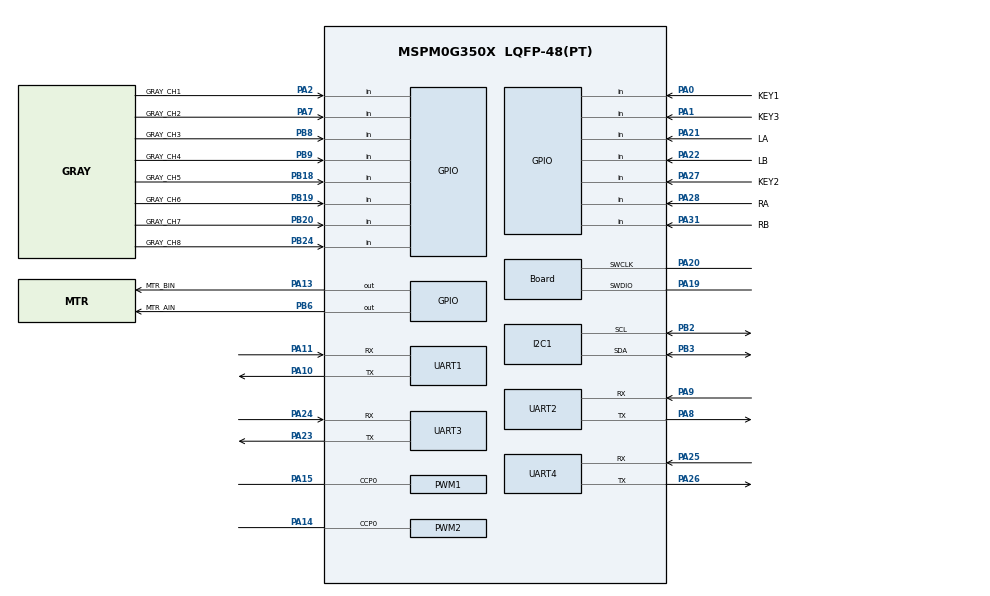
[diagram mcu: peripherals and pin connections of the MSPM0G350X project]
/**
 * @cliArgs --device "MSPM0G350X" --part "Default" --package "LQFP-48(PT)" --product "mspm0_sdk@2.10.00.04"
 * @versions {"tool":"1.26.2+4477"}
 */

/**
 * Import the modules used in this configuration.
 */
const GPIO    = scripting.addModule("/ti/driverlib/GPIO", {}, false);
const GPIO1   = GPIO.addInstance();
const GPIO2   = GPIO.addInstance();
const GPIO3   = GPIO.addInstance();
const GPIO4   = GPIO.addInstance();
const GPIO5   = GPIO.addInstance();
const GPIO6   = GPIO.addInstance();
const I2C     = scripting.addModule("/ti/driverlib/I2C", {}, false);
const I2C1    = I2C.addInstance();
const PWM     = scripting.addModule("/ti/driverlib/PWM", {}, false);
const PWM1    = PWM.addInstance();
const PWM2    = PWM.addInstance();
const SYSCTL  = scripting.addModule("/ti/driverlib/SYSCTL");
const SYSTICK = scripting.addModule("/ti/driverlib/SYSTICK");
const TIMER   = scripting.addModule("/ti/driverlib/TIMER", {}, false);
const TIMER1  = TIMER.addInstance();
const UART    = scripting.addModule("/ti/driverlib/UART", {}, false);
const UART1   = UART.addInstance();
const UART2   = UART.addInstance();
const UART3   = UART.addInstance();
const UART4   = UART.addInstance();

/**
 * Write custom configuration values to the imported modules.
 */
GPIO1.$name                               = "KEY";
GPIO1.port                                = "PORTA";
GPIO1.associatedPins.create(3);
GPIO1.associatedPins[0].$name             = "KEY1";
GPIO1.associatedPins[0].direction         = "INPUT";
GPIO1.associatedPins[0].polarity          = "FALL";
GPIO1.associatedPins[0].interruptPriority = "1";
GPIO1.associatedPins[0].pin.$assign       = "PA0";
GPIO1.associatedPins[1].$name             = "KEY2";
GPIO1.associatedPins[1].direction         = "INPUT";
GPIO1.associatedPins[1].pin.$assign       = "PA27";
GPIO1.associatedPins[2].$name             = "KEY3";
GPIO1.associatedPins[2].direction         = "INPUT";
GPIO1.associatedPins[2].pin.$assign       = "PA1";

const Board                       = scripting.addModule("/ti/driverlib/Board", {}, false);
Board.peripheral.$assign          = "DEBUGSS";
Board.peripheral.swclkPin.$assign = "PA20";
Board.peripheral.swdioPin.$assign = "PA19";

GPIO2.$name                         = "MOTOR_DIR_B";
GPIO2.port                          = "PORTA";
GPIO2.associatedPins[0].$name       = "MTR_BIN";
GPIO2.associatedPins[0].pin.$assign = "PA13";

GPIO3.$name                         = "MOTOR_DIR_A";
GPIO3.port                          = "PORTB";
GPIO3.associatedPins[0].$name       = "MTR_AIN";
GPIO3.associatedPins[0].pin.$assign = "PB6";

GPIO4.$name                              = "GRAYSCALE_A";
GPIO4.port                               = "PORTA";
GPIO4.associatedPins.create(2);
GPIO4.associatedPins[0].$name            = "GRAY_CH1";
GPIO4.associatedPins[0].direction        = "INPUT";
GPIO4.associatedPins[0].internalResistor = "PULL_UP";
GPIO4.associatedPins[0].pin.$assign      = "PA2";
GPIO4.associatedPins[1].$name            = "GRAY_CH2";
GPIO4.associatedPins[1].direction        = "INPUT";
GPIO4.associatedPins[1].internalResistor = "PULL_UP";
GPIO4.associatedPins[1].pin.$assign      = "PA7";

GPIO5.$name                              = "GRAYSCALE_B";
GPIO5.port                               = "PORTB";
GPIO5.associatedPins.create(6);
GPIO5.associatedPins[0].$name            = "GRAY_CH3";
GPIO5.associatedPins[0].direction        = "INPUT";
GPIO5.associatedPins[0].internalResistor = "PULL_UP";
GPIO5.associatedPins[0].pin.$assign      = "PB8";
GPIO5.associatedPins[1].$name            = "GRAY_CH4";
GPIO5.associatedPins[1].direction        = "INPUT";
GPIO5.associatedPins[1].internalResistor = "PULL_UP";
GPIO5.associatedPins[1].pin.$assign      = "PB9";
GPIO5.associatedPins[2].$name            = "GRAY_CH5";
GPIO5.associatedPins[2].direction        = "INPUT";
GPIO5.associatedPins[2].internalResistor = "PULL_UP";
GPIO5.associatedPins[2].pin.$assign      = "PB18";
GPIO5.associatedPins[3].$name            = "GRAY_CH6";
GPIO5.associatedPins[3].direction        = "INPUT";
GPIO5.associatedPins[3].internalResistor = "PULL_UP";
GPIO5.associatedPins[3].pin.$assign      = "PB19";
GPIO5.associatedPins[4].$name            = "GRAY_CH7";
GPIO5.associatedPins[4].direction        = "INPUT";
GPIO5.associatedPins[4].internalResistor = "PULL_UP";
GPIO5.associatedPins[4].pin.$assign      = "PB20";
GPIO5.associatedPins[5].$name            = "GRAY_CH8";
GPIO5.associatedPins[5].direction        = "INPUT";
GPIO5.associatedPins[5].internalResistor = "PULL_UP";
GPIO5.associatedPins[5].pin.$assign      = "PB24";

GPIO6.$name                               = "ENC";
GPIO6.port                                = "PORTA";
GPIO6.associatedPins.create(4);
GPIO6.associatedPins[0].$name             = "LA";
GPIO6.associatedPins[0].direction         = "INPUT";
GPIO6.associatedPins[0].interruptPriority = "1";
GPIO6.associatedPins[0].polarity          = "RISE_FALL";
GPIO6.associatedPins[0].interruptEn       = true;
GPIO6.associatedPins[0].internalResistor  = "PULL_UP";
GPIO6.associatedPins[0].pin.$assign       = "PA21";
GPIO6.associatedPins[1].$name             = "LB";
GPIO6.associatedPins[1].direction         = "INPUT";
GPIO6.associatedPins[1].interruptEn       = true;
GPIO6.associatedPins[1].interruptPriority = "1";
GPIO6.associatedPins[1].polarity          = "RISE_FALL";
GPIO6.associatedPins[1].internalResistor  = "PULL_UP";
GPIO6.associatedPins[1].pin.$assign       = "PA22";
GPIO6.associatedPins[2].$name             = "RA";
GPIO6.associatedPins[2].direction         = "INPUT";
GPIO6.associatedPins[2].interruptEn       = true;
GPIO6.associatedPins[2].interruptPriority = "1";
GPIO6.associatedPins[2].polarity          = "RISE_FALL";
GPIO6.associatedPins[2].internalResistor  = "PULL_UP";
GPIO6.associatedPins[2].pin.$assign       = "PA28";
GPIO6.associatedPins[3].$name             = "RB";
GPIO6.associatedPins[3].direction         = "INPUT";
GPIO6.associatedPins[3].interruptEn       = true;
GPIO6.associatedPins[3].interruptPriority = "1";
GPIO6.associatedPins[3].polarity          = "RISE_FALL";
GPIO6.associatedPins[3].internalResistor  = "PULL_UP";
GPIO6.associatedPins[3].pin.$assign       = "PA31";

I2C1.$name                             = "I2C";
I2C1.basicEnableController             = true;
I2C1.basicControllerStandardBusSpeed   = "Fast";
I2C1.peripheral.$assign                = "I2C1";
I2C1.peripheral.sdaPin.$assign         = "PB3";
I2C1.peripheral.sclPin.$assign         = "PB2";
I2C1.sdaPinConfig.hideOutputInversion  = scripting.forceWrite(false);
I2C1.sdaPinConfig.onlyInternalResistor = scripting.forceWrite(false);
I2C1.sdaPinConfig.passedPeripheralType = scripting.forceWrite("Digital");
I2C1.sdaPinConfig.$name                = "ti_driverlib_gpio_GPIOPinGeneric9";
I2C1.sdaPinConfig.enableConfig         = true;
I2C1.sdaPinConfig.internalResistor     = "PULL_UP";
I2C1.sclPinConfig.hideOutputInversion  = scripting.forceWrite(false);
I2C1.sclPinConfig.onlyInternalResistor = scripting.forceWrite(false);
I2C1.sclPinConfig.passedPeripheralType = scripting.forceWrite("Digital");
I2C1.sclPinConfig.$name                = "ti_driverlib_gpio_GPIOPinGeneric11";
I2C1.sclPinConfig.enableConfig         = true;
I2C1.sclPinConfig.internalResistor     = "PULL_UP";

PWM1.$name                              = "PWM_MOTOR_L";
PWM1.ccIndex                            = [0];
PWM1.clockDivider                       = 8;
PWM1.timerCount                         = 200;
PWM1.PWM_CHANNEL_0.$name                = "ti_driverlib_pwm_PWMTimerCC0";
PWM1.ccp0PinConfig.direction            = scripting.forceWrite("OUTPUT");
PWM1.ccp0PinConfig.hideOutputInversion  = scripting.forceWrite(false);
PWM1.ccp0PinConfig.onlyInternalResistor = scripting.forceWrite(false);
PWM1.ccp0PinConfig.passedPeripheralType = scripting.forceWrite("Digital");
PWM1.ccp0PinConfig.$name                = "ti_driverlib_gpio_GPIOPinGeneric8";
PWM1.peripheral.ccp0Pin.$assign         = "PA15";

PWM2.$name                              = "PWM_MOTOR_R";
PWM2.ccIndex                            = [0];
PWM2.clockDivider                       = 8;
PWM2.timerCount                         = 200;
PWM2.PWM_CHANNEL_0.$name                = "ti_driverlib_pwm_PWMTimerCC2";
PWM2.ccp0PinConfig.direction            = scripting.forceWrite("OUTPUT");
PWM2.ccp0PinConfig.hideOutputInversion  = scripting.forceWrite(false);
PWM2.ccp0PinConfig.onlyInternalResistor = scripting.forceWrite(false);
PWM2.ccp0PinConfig.passedPeripheralType = scripting.forceWrite("Digital");
PWM2.ccp0PinConfig.$name                = "ti_driverlib_gpio_GPIOPinGeneric10";
PWM2.peripheral.$assign                 = "TIMG12";
PWM2.peripheral.ccp0Pin.$assign         = "PA14";

SYSCTL.forceDefaultClkConfig = true;

SYSTICK.periodEnable      = true;
SYSTICK.systickEnable     = true;
SYSTICK.interruptPriority = "0";
SYSTICK.period            = 32;

TIMER1.$name              = "TIMER_SYS";
TIMER1.timerClkDiv        = 8;
TIMER1.timerStartTimer    = true;
TIMER1.timerMode          = "PERIODIC";
TIMER1.interrupts         = ["ZERO"];
TIMER1.interruptPriority  = "1";
TIMER1.timerPeriod        = "10 ms";
TIMER1.peripheral.$assign = "TIMA0";

UART1.$name                            = "UART_DEBUG";
UART1.targetBaudRate                   = 115200;
UART1.enabledInterrupts                = ["RX"];
UART1.interruptPriority                = "2";
UART1.peripheral.$assign               = "UART0";
UART1.peripheral.rxPin.$assign         = "PA11";
UART1.peripheral.txPin.$assign         = "PA10";
UART1.txPinConfig.direction            = scripting.forceWrite("OUTPUT");
UART1.txPinConfig.hideOutputInversion  = scripting.forceWrite(false);
UART1.txPinConfig.onlyInternalResistor = scripting.forceWrite(false);
UART1.txPinConfig.passedPeripheralType = scripting.forceWrite("Digital");
UART1.txPinConfig.$name                = "ti_driverlib_gpio_GPIOPinGeneric0";
UART1.rxPinConfig.hideOutputInversion  = scripting.forceWrite(false);
UART1.rxPinConfig.onlyInternalResistor = scripting.forceWrite(false);
UART1.rxPinConfig.passedPeripheralType = scripting.forceWrite("Digital");
UART1.rxPinConfig.$name                = "ti_driverlib_gpio_GPIOPinGeneric1";

UART2.$name                            = "UART_GYRO";
UART2.targetBaudRate                   = 115200;
UART2.enabledInterrupts                = ["RX"];
UART2.interruptPriority                = "2";
UART2.peripheral.$assign               = "UART1";
UART2.peripheral.rxPin.$assign         = "PA9";
UART2.peripheral.txPin.$assign         = "PA8";
UART2.txPinConfig.direction            = scripting.forceWrite("OUTPUT");
UART2.txPinConfig.hideOutputInversion  = scripting.forceWrite(false);
UART2.txPinConfig.onlyInternalResistor = scripting.forceWrite(false);
UART2.txPinConfig.passedPeripheralType = scripting.forceWrite("Digital");
UART2.txPinConfig.$name                = "ti_driverlib_gpio_GPIOPinGeneric2";
UART2.rxPinConfig.hideOutputInversion  = scripting.forceWrite(false);
UART2.rxPinConfig.onlyInternalResistor = scripting.forceWrite(false);
UART2.rxPinConfig.passedPeripheralType = scripting.forceWrite("Digital");
UART2.rxPinConfig.$name                = "ti_driverlib_gpio_GPIOPinGeneric3";

UART3.$name                            = "UART_BT";
UART3.enabledInterrupts                = ["RX"];
UART3.interruptPriority                = "2";
UART3.peripheral.$assign               = "UART2";
UART3.peripheral.rxPin.$assign         = "PA24";
UART3.peripheral.txPin.$assign         = "PA23";
UART3.txPinConfig.direction            = scripting.forceWrite("OUTPUT");
UART3.txPinConfig.hideOutputInversion  = scripting.forceWrite(false);
UART3.txPinConfig.onlyInternalResistor = scripting.forceWrite(false);
UART3.txPinConfig.passedPeripheralType = scripting.forceWrite("Digital");
UART3.txPinConfig.$name                = "ti_driverlib_gpio_GPIOPinGeneric4";
UART3.rxPinConfig.hideOutputInversion  = scripting.forceWrite(false);
UART3.rxPinConfig.onlyInternalResistor = scripting.forceWrite(false);
UART3.rxPinConfig.passedPeripheralType = scripting.forceWrite("Digital");
UART3.rxPinConfig.$name                = "ti_driverlib_gpio_GPIOPinGeneric5";

UART4.$name                            = "UART_COMM";
UART4.targetBaudRate                   = 115200;
UART4.enabledInterrupts                = ["RX"];
UART4.interruptPriority                = "2";
UART4.peripheral.$assign               = "UART3";
UART4.peripheral.rxPin.$assign         = "PA25";
UART4.peripheral.txPin.$assign         = "PA26";
UART4.txPinConfig.direction            = scripting.forceWrite("OUTPUT");
UART4.txPinConfig.hideOutputInversion  = scripting.forceWrite(false);
UART4.txPinConfig.onlyInternalResistor = scripting.forceWrite(false);
UART4.txPinConfig.passedPeripheralType = scripting.forceWrite("Digital");
UART4.txPinConfig.$name                = "ti_driverlib_gpio_GPIOPinGeneric6";
UART4.rxPinConfig.hideOutputInversion  = scripting.forceWrite(false);
UART4.rxPinConfig.onlyInternalResistor = scripting.forceWrite(false);
UART4.rxPinConfig.passedPeripheralType = scripting.forceWrite("Digital");
UART4.rxPinConfig.$name                = "ti_driverlib_gpio_GPIOPinGeneric7";

const ProjectConfig              = scripting.addModule("/ti/project_config/ProjectConfig", {}, false);
ProjectConfig.migrationCondition = true;

/**
 * Pinmux solution for unlocked pins/peripherals. This ensures that minor changes to the automatic solver in a future
 * version of the tool will not impact the pinmux you originally saw.  These lines can be completely deleted in order to
 * re-solve from scratch.
 */
PWM1.peripheral.$suggestSolution   = "TIMA1";
SYSCTL.peripheral.$suggestSolution = "SYSCTL";
